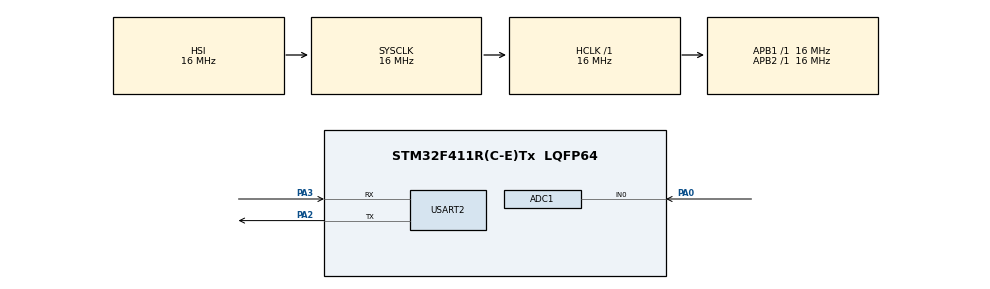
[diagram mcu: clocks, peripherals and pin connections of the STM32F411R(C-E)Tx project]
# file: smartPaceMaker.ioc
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Mcu.Family=STM32F4
Dma.ADC1.0.Instance=DMA2_Stream0
RCC.CortexFreq_Value=16000000
ADC1.ContinuousConvMode=ENABLE
ADC1.SamplingTime-6\#ChannelRegularConversion=ADC_SAMPLETIME_3CYCLES
ProjectManager.StackSize=0x400
PA0-WKUP.Signal=ADCx_IN0
PA3.Mode=Asynchronous
Dma.ADC1.0.PeriphDataAlignment=DMA_PDATAALIGN_HALFWORD
ProjectManager.TargetToolchain=STM32CubeIDE
Dma.ADC1.0.Mode=DMA_CIRCULAR
RCC.HCLKFreq_Value=16000000
RCC.APB2TimFreq_Value=16000000
Dma.ADC1.0.Priority=DMA_PRIORITY_LOW
Dma.ADC1.0.Direction=DMA_PERIPH_TO_MEMORY
NVIC.DMA2_Stream0_IRQn=true\:0\:0\:false\:false\:true\:false\:true
RCC.LSE_VALUE=32768
Dma.ADC1.0.MemDataAlignment=DMA_MDATAALIGN_HALFWORD
RCC.AHBFreq_Value=16000000
RCC.HSE_VALUE=25000000
ADC1.ScanConvMode=ENABLE
board=custom
RCC.VCOOutputFreq_Value=192000000
ADC1.Channel-6\#ChannelRegularConversion=ADC_CHANNEL_0
RCC.APB2Freq_Value=16000000
VP_TIM2_VS_ClockSourceINT.Mode=Internal
Dma.ADC1.0.PeriphInc=DMA_PINC_DISABLE
NVIC.TIM2_IRQn=true\:0\:0\:false\:false\:true\:true\:true
SH.ADCx_IN0.0=ADC1_IN0,IN0
ADC1.DMAContinuousRequests=ENABLE
TIM2.Period=1999
Mcu.Name=STM32F411R(C-E)Tx
PA2.Signal=USART2_TX
ADC1.ExternalTrigConv=ADC_EXTERNALTRIGCONV_T2_TRGO
RCC.SYSCLKFreq_VALUE=16000000
Mcu.Package=LQFP64
TIM2.Prescaler=15999
ADC1.master=1
USART2.VirtualMode=VM_ASYNC
Dma.ADC1.0.MemInc=DMA_MINC_ENABLE
ProjectManager.HeapSize=0x200
RCC.HSI_VALUE=16000000
NVIC.PriorityGroup=NVIC_PRIORITYGROUP_4
TIM2.TIM_MasterOutputTrigger=TIM_TRGO_UPDATE
ADC1.NbrOfConversionFlag=1
TIM2.TIM_MasterSlaveMode=TIM_MASTERSLAVEMODE_ENABLE
RCC.APB1TimFreq_Value=16000000
PA2.Mode=Asynchronous
Dma.ADC1.0.FIFOMode=DMA_FIFOMODE_DISABLE
RCC.APB1Freq_Value=16000000
Dma.Request0=ADC1
ADC1.Rank-6\#ChannelRegularConversion=1
PA3.Signal=USART2_RX

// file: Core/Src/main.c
/* USER CODE BEGIN Header */
/**
  ******************************************************************************
  * @file           : main.c
  * @brief          : Main program body
  ******************************************************************************
  * @attention
  *
  * <h2><center>&copy; Copyright (c) 2021 STMicroelectronics.
  * All rights reserved.</center></h2>
  *
  * This software component is licensed by ST under BSD 3-Clause license,
  * the "License"; You may not use this file except in compliance with the
  * License. You may obtain a copy of the License at:
  *                        opensource.org/licenses/BSD-3-Clause
  *
  ******************************************************************************
  */
/* USER CODE END Header */
#include "main.h"

/* USER CODE BEGIN Includes */
#include <string.h>
#include <stdio.h>

/* USER CODE END Includes */

/* USER CODE BEGIN PD */
#define ADC_BUF_SIZE 2048 // ADC@200Hz can hold 20secs of data
/* USER CODE END PD */

ADC_HandleTypeDef hadc1;
DMA_HandleTypeDef hdma_adc1;

TIM_HandleTypeDef htim2;

UART_HandleTypeDef huart2;

/* USER CODE BEGIN PV */
uint16_t ADC_buffer[ADC_BUF_SIZE];
uint16_t ADC_buffer_index;
char msg[10];
/* USER CODE END PV */

void SystemClock_Config(void);
static void MX_GPIO_Init(void);
static void MX_DMA_Init(void);
static void MX_ADC1_Init(void);
static void MX_TIM2_Init(void);
static void MX_USART2_UART_Init(void);

int main(void)
{
  /* USER CODE BEGIN 1 */
	/*uint16_t pulse_sensor_raw;
	uint8_t txdata[30] = "LOL u got me \r\n";
	char msg[10];*/
  /* USER CODE END 1 */

  /* MCU Configuration--------------------------------------------------------*/

  /* Reset of all peripherals, Initializes the Flash interface and the Systick. */
  HAL_Init();

  /* Configure the system clock */
  SystemClock_Config();

  /* Initialize all configured peripherals */
  MX_GPIO_Init();
  MX_DMA_Init();
  MX_ADC1_Init();
  MX_TIM2_Init();
  MX_USART2_UART_Init();
  /* USER CODE BEGIN 2 */
  /*if(HAL_OK != HAL_ADCEx_Calibration_Start(&hadc1)) //Calibrate ADC
	  Error_Handler();*/

  if(HAL_OK != HAL_ADC_Start_DMA(&hadc1, ADC_buffer, ADC_BUF_SIZE))
	  Error_Handler();

  if(HAL_OK != HAL_TIM_Base_Start(&htim2))
	  Error_Handler();
  /* USER CODE END 2 */

  /* Infinite loop */
  while (1)
  {

    /* USER CODE BEGIN 3 */
	  /* ADC -> CPU Polling -> Buf in mem -> CPU -> UART
	  //HAL_GPIO_WritePin(GPIOA, GPIO_PIN_12, GPIO_PIN_SET);
	  HAL_ADC_Start(&hadc1);
	  HAL_ADC_PollForConversion(&hadc1,HAL_MAX_DELAY);
	  pulse_sensor_raw = HAL_ADC_GetValue(&hadc1);

	  //Transmit over  uart
	  sprintf(msg, "%hu\r\n", pulse_sensor_raw);
	  HAL_UART_Transmit(&huart2, (uint8_t*)msg, strlen(msg), HAL_MAX_DELAY);
	  HAL_Delay(1);*/

	  /*
	  sprintf(msg,"%hu\r\n",(uint16_t)3304);
	  HAL_UART_Transmit(&huart2, (uint8_t*)msg, strlen(msg), HAL_MAX_DELAY);*/

	  HAL_Delay(1);

  }
  /* USER CODE END 3 */
}

void SystemClock_Config(void)
{
  RCC_OscInitTypeDef RCC_OscInitStruct = {0};
  RCC_ClkInitTypeDef RCC_ClkInitStruct = {0};

  /** Configure the main internal regulator output voltage
  */
  __HAL_RCC_PWR_CLK_ENABLE();
  __HAL_PWR_VOLTAGESCALING_CONFIG(PWR_REGULATOR_VOLTAGE_SCALE1);
  /** Initializes the RCC Oscillators according to the specified parameters
  * in the RCC_OscInitTypeDef structure.
  */
  RCC_OscInitStruct.OscillatorType = RCC_OSCILLATORTYPE_HSI;
  RCC_OscInitStruct.HSIState = RCC_HSI_ON;
  RCC_OscInitStruct.HSICalibrationValue = RCC_HSICALIBRATION_DEFAULT;
  RCC_OscInitStruct.PLL.PLLState = RCC_PLL_NONE;
  if (HAL_RCC_OscConfig(&RCC_OscInitStruct) != HAL_OK)
  {
    Error_Handler();
  }
  /** Initializes the CPU, AHB and APB buses clocks
  */
  RCC_ClkInitStruct.ClockType = RCC_CLOCKTYPE_HCLK|RCC_CLOCKTYPE_SYSCLK
                              |RCC_CLOCKTYPE_PCLK1|RCC_CLOCKTYPE_PCLK2;
  RCC_ClkInitStruct.SYSCLKSource = RCC_SYSCLKSOURCE_HSI;
  RCC_ClkInitStruct.AHBCLKDivider = RCC_SYSCLK_DIV1;
  RCC_ClkInitStruct.APB1CLKDivider = RCC_HCLK_DIV1;
  RCC_ClkInitStruct.APB2CLKDivider = RCC_HCLK_DIV1;

  if (HAL_RCC_ClockConfig(&RCC_ClkInitStruct, FLASH_LATENCY_0) != HAL_OK)
  {
    Error_Handler();
  }
}

static void MX_ADC1_Init(void)
{

  ADC_ChannelConfTypeDef sConfig = {0};

  /** Configure the global features of the ADC (Clock, Resolution, Data Alignment and number of conversion)
  */
  hadc1.Instance = ADC1;
  hadc1.Init.ClockPrescaler = ADC_CLOCK_SYNC_PCLK_DIV2;
  hadc1.Init.Resolution = ADC_RESOLUTION_12B;
  hadc1.Init.ScanConvMode = ENABLE;
  hadc1.Init.ContinuousConvMode = ENABLE;
  hadc1.Init.DiscontinuousConvMode = DISABLE;
  hadc1.Init.ExternalTrigConvEdge = ADC_EXTERNALTRIGCONVEDGE_RISING;
  hadc1.Init.ExternalTrigConv = ADC_EXTERNALTRIGCONV_T2_TRGO;
  hadc1.Init.DataAlign = ADC_DATAALIGN_RIGHT;
  hadc1.Init.NbrOfConversion = 1;
  hadc1.Init.DMAContinuousRequests = ENABLE;
  hadc1.Init.EOCSelection = ADC_EOC_SINGLE_CONV;
  if (HAL_ADC_Init(&hadc1) != HAL_OK)
  {
    Error_Handler();
  }
  /** Configure for the selected ADC regular channel its corresponding rank in the sequencer and its sample time.
  */
  sConfig.Channel = ADC_CHANNEL_0;
  sConfig.Rank = 1;
  sConfig.SamplingTime = ADC_SAMPLETIME_3CYCLES;
  if (HAL_ADC_ConfigChannel(&hadc1, &sConfig) != HAL_OK)
  {
    Error_Handler();
  }

}

static void MX_TIM2_Init(void)
{

  TIM_ClockConfigTypeDef sClockSourceConfig = {0};
  TIM_MasterConfigTypeDef sMasterConfig = {0};

  htim2.Instance = TIM2;
  htim2.Init.Prescaler = 15999;
  htim2.Init.CounterMode = TIM_COUNTERMODE_UP;
  htim2.Init.Period = 1999;
  htim2.Init.ClockDivision = TIM_CLOCKDIVISION_DIV1;
  htim2.Init.AutoReloadPreload = TIM_AUTORELOAD_PRELOAD_DISABLE;
  if (HAL_TIM_Base_Init(&htim2) != HAL_OK)
  {
    Error_Handler();
  }
  sClockSourceConfig.ClockSource = TIM_CLOCKSOURCE_INTERNAL;
  if (HAL_TIM_ConfigClockSource(&htim2, &sClockSourceConfig) != HAL_OK)
  {
    Error_Handler();
  }
  sMasterConfig.MasterOutputTrigger = TIM_TRGO_UPDATE;
  sMasterConfig.MasterSlaveMode = TIM_MASTERSLAVEMODE_ENABLE;
  if (HAL_TIMEx_MasterConfigSynchronization(&htim2, &sMasterConfig) != HAL_OK)
  {
    Error_Handler();
  }

}

static void MX_USART2_UART_Init(void)
{

  huart2.Instance = USART2;
  huart2.Init.BaudRate = 115200;
  huart2.Init.WordLength = UART_WORDLENGTH_8B;
  huart2.Init.StopBits = UART_STOPBITS_1;
  huart2.Init.Parity = UART_PARITY_NONE;
  huart2.Init.Mode = UART_MODE_TX_RX;
  huart2.Init.HwFlowCtl = UART_HWCONTROL_NONE;
  huart2.Init.OverSampling = UART_OVERSAMPLING_16;
  if (HAL_UART_Init(&huart2) != HAL_OK)
  {
    Error_Handler();
  }

}

static void MX_DMA_Init(void)
{

  /* DMA controller clock enable */
  __HAL_RCC_DMA2_CLK_ENABLE();

  /* DMA interrupt init */
  /* DMA2_Stream0_IRQn interrupt configuration */
  HAL_NVIC_SetPriority(DMA2_Stream0_IRQn, 0, 0);
  HAL_NVIC_EnableIRQ(DMA2_Stream0_IRQn);

}

static void MX_GPIO_Init(void)
{

  /* GPIO Ports Clock Enable */
  __HAL_RCC_GPIOA_CLK_ENABLE();

}

/* USER CODE BEGIN 4 */

// Called when buffer is half full
void HAL_ADC_ConvHalfCpltCallback(ADC_HandleTypeDef* hadc){
	//CPU Code
	if(HAL_ADC_Stop_DMA(&hadc1) != HAL_OK)
		Error_Handler();
	for(ADC_buffer_index = 0; ADC_buffer_index < ADC_BUF_SIZE; ++ADC_buffer_index){
		sprintf(msg,"%u -> %hu\r\n",ADC_buffer_index,ADC_buffer[ADC_buffer_index]);
		HAL_UART_Transmit(&huart2, (uint8_t*)msg, strlen(msg), HAL_MAX_DELAY);
	}

}
// Called when buffer is full
void HAL_ADC_ConvCpltCallback(ADC_HandleTypeDef* hadc){
	//CPU Code
	if(HAL_ADC_Stop_DMA(&hadc1) != HAL_OK)
			Error_Handler();
	for(ADC_buffer_index = 0; ADC_buffer_index < ADC_BUF_SIZE; ++ADC_buffer_index){
		sprintf(msg,"%u -> %hu\r\n",ADC_buffer_index,ADC_buffer[ADC_buffer_index]);
		HAL_UART_Transmit(&huart2, (uint8_t*)msg, strlen(msg), HAL_MAX_DELAY);
	}

}
/* USER CODE END 4 */

void Error_Handler(void)
{
  __disable_irq();
  while (1)
  {
  }
}

/************************ (C) COPYRIGHT STMicroelectronics *****END OF FILE****/
